VERSION ""

NS_ :

BS_:

BU_:

BO_ 388 Feedback_1: 8 Vector__XXX
 SG_ Wheel_Angle : 15|16@0+ (0.005,-81.92) [0|0] "" Vector__XXX
 SG_ Wheel_speed : 7|8@0+ (1,0) [0|0] "" Vector__XXX

BO_ 384 Not_important_4: 8 Vector__XXX

BO_ 386 Not_important_1: 8 Vector__XXX

BO_ 385 Not_important_2: 8 Vector__XXX

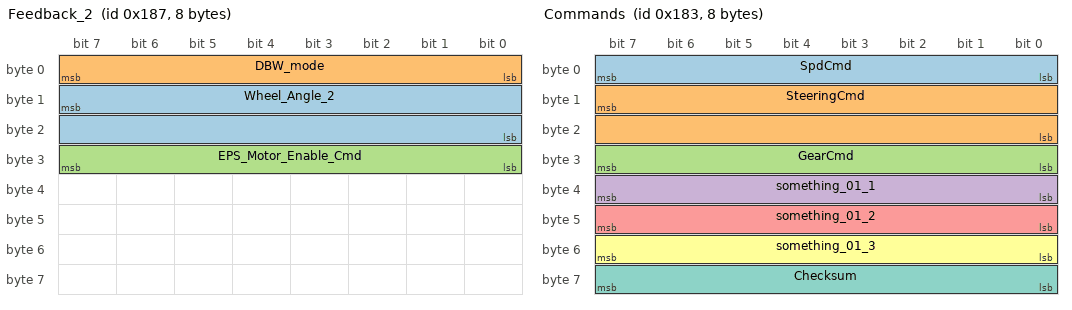
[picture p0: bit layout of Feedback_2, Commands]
BO_ 391 Feedback_2: 8 Vector__XXX
 SG_ Wheel_Angle_2 : 15|16@0+ (0.005,-81.92) [0|0] "" Vector__XXX
 SG_ DBW_mode : 7|8@0+ (1,0) [0|0] "" Vector__XXX
 SG_ EPS_Motor_Enable_Cmd : 31|8@0+ (1,0) [0|0] "" Vector__XXX

BO_ 392 Not_important_3: 8 Vector__XXX

BO_ 387 Commands: 8 Vector__XXX
 SG_ SpdCmd : 7|8@0+ (1,0) [0|0] "" Vector__XXX
 SG_ SteeringCmd : 15|16@0+ (0.005,-81.92) [0|0] "" Vector__XXX
 SG_ GearCmd : 31|8@0+ (1,0) [0|0] "" Vector__XXX
 SG_ something_01_1 : 39|8@0+ (1,0) [0|0] "" Vector__XXX
 SG_ something_01_2 : 47|8@0+ (1,0) [0|0] "" Vector__XXX
 SG_ something_01_3 : 55|8@0+ (1,0) [0|0] "" Vector__XXX
 SG_ Checksum : 63|8@0+ (1,0) [0|0] "" Vector__XXX

VAL_ 391 DBW_mode 0 "NA" 1 "Manual" 2 "Automatic" ;
VAL_ 391 EPS_Motor_Enable_Cmd 0 "OFF" 92 "ON" ;
VAL_ 387 GearCmd 1 "Neutral" 2 "Drive" 3 "Reverse" ;
